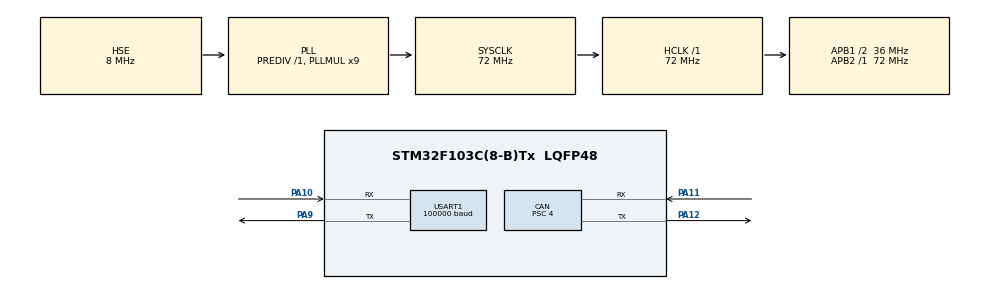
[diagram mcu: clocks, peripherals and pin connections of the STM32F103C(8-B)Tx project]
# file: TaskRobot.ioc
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CAN.BS1=CAN_BS1_6TQ
CAN.BS2=CAN_BS2_2TQ
CAN.CalculateBaudRate=1000000
CAN.CalculateTimeBit=1000
CAN.CalculateTimeQuantum=111.11111111111111
CAN.Prescaler=4
Dma.Request0=USART1_RX
Dma.USART1_RX.0.Direction=DMA_PERIPH_TO_MEMORY
Dma.USART1_RX.0.Instance=DMA1_Channel5
Dma.USART1_RX.0.MemDataAlignment=DMA_MDATAALIGN_BYTE
Dma.USART1_RX.0.MemInc=DMA_MINC_ENABLE
Dma.USART1_RX.0.Mode=DMA_NORMAL
Dma.USART1_RX.0.PeriphDataAlignment=DMA_PDATAALIGN_BYTE
Dma.USART1_RX.0.PeriphInc=DMA_PINC_DISABLE
Dma.USART1_RX.0.Priority=DMA_PRIORITY_LOW
Mcu.Family=STM32F1
Mcu.Name=STM32F103C(8-B)Tx
Mcu.Package=LQFP48
NVIC.DMA1_Channel5_IRQn=true\:0\:0\:false\:false\:true\:false\:true\:true
NVIC.PriorityGroup=NVIC_PRIORITYGROUP_4
NVIC.USART1_IRQn=true\:0\:0\:false\:false\:true\:true\:true\:true
NVIC.USB_LP_CAN1_RX0_IRQn=true\:0\:0\:false\:false\:true\:true\:true\:true
PA10.Mode=Asynchronous
PA10.Signal=USART1_RX
PA11.Mode=CAN_Activate
PA11.Signal=CAN_RX
PA12.Mode=CAN_Activate
PA12.Signal=CAN_TX
PA9.Mode=Asynchronous
PA9.Signal=USART1_TX
PD0-OSC_IN.Mode=HSE-External-Oscillator
PD0-OSC_IN.Signal=RCC_OSC_IN
PD1-OSC_OUT.Mode=HSE-External-Oscillator
PD1-OSC_OUT.Signal=RCC_OSC_OUT
ProjectManager.HeapSize=0x200
ProjectManager.StackSize=0x400
ProjectManager.TargetToolchain=Makefile
RCC.AHBFreq_Value=72000000
RCC.APB1CLKDivider=RCC_HCLK_DIV2
RCC.APB1Freq_Value=36000000
RCC.APB1TimFreq_Value=72000000
RCC.APB2Freq_Value=72000000
RCC.APB2TimFreq_Value=72000000
RCC.HCLKFreq_Value=72000000
RCC.PLLMUL=RCC_PLL_MUL9
RCC.PLLSourceVirtual=RCC_PLLSOURCE_HSE
RCC.SYSCLKFreq_VALUE=72000000
RCC.SYSCLKSource=RCC_SYSCLKSOURCE_PLLCLK
RCC.USBFreq_Value=72000000
USART1.BaudRate=100000
USART1.Parity=PARITY_EVEN
USART1.VirtualMode=VM_ASYNC
USART1.WordLength=WORDLENGTH_9B
VP_SYS_VS_ND.Mode=No_Debug
board=custom

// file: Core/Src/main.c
/* USER CODE BEGIN Header */
/**
  ******************************************************************************
  * @file           : main.c
  * @brief          : Main program body
  ******************************************************************************
  * @attention
  *
  * Copyright (c) 2023 STMicroelectronics.
  * All rights reserved.
  *
  * This software is licensed under terms that can be found in the LICENSE file
  * in the root directory of this software component.
  * If no LICENSE file comes with this software, it is provided AS-IS.
  *
  ******************************************************************************
  */
/* USER CODE END Header */
#include "main.h"
#include "can.h"
#include "dma.h"
#include "usart.h"
#include "gpio.h"

/* USER CODE BEGIN Includes */
// #include "cppMain.hpp"
/* USER CODE END Includes */

void SystemClock_Config(void);

int main(void)
{

  /* MCU Configuration--------------------------------------------------------*/

  /* Reset of all peripherals, Initializes the Flash interface and the Systick. */
  HAL_Init();

  /* Configure the system clock */
  SystemClock_Config();

  /* Initialize all configured peripherals */
  MX_GPIO_Init();
  MX_DMA_Init();
  MX_CAN_Init();
  MX_USART1_UART_Init();

  /* Infinite loop */
  /* USER CODE BEGIN WHILE */
  extern int cppMain();
  cppMain();

  while (1)
  {
    /* USER CODE END WHILE */

  }
}

void SystemClock_Config(void)
{
  RCC_OscInitTypeDef RCC_OscInitStruct = {0};
  RCC_ClkInitTypeDef RCC_ClkInitStruct = {0};

  /** Initializes the RCC Oscillators according to the specified parameters
  * in the RCC_OscInitTypeDef structure.
  */
  RCC_OscInitStruct.OscillatorType = RCC_OSCILLATORTYPE_HSE;
  RCC_OscInitStruct.HSEState = RCC_HSE_ON;
  RCC_OscInitStruct.HSEPredivValue = RCC_HSE_PREDIV_DIV1;
  RCC_OscInitStruct.HSIState = RCC_HSI_ON;
  RCC_OscInitStruct.PLL.PLLState = RCC_PLL_ON;
  RCC_OscInitStruct.PLL.PLLSource = RCC_PLLSOURCE_HSE;
  RCC_OscInitStruct.PLL.PLLMUL = RCC_PLL_MUL9;
  if (HAL_RCC_OscConfig(&RCC_OscInitStruct) != HAL_OK)
  {
    Error_Handler();
  }

  /** Initializes the CPU, AHB and APB buses clocks
  */
  RCC_ClkInitStruct.ClockType = RCC_CLOCKTYPE_HCLK|RCC_CLOCKTYPE_SYSCLK
                              |RCC_CLOCKTYPE_PCLK1|RCC_CLOCKTYPE_PCLK2;
  RCC_ClkInitStruct.SYSCLKSource = RCC_SYSCLKSOURCE_PLLCLK;
  RCC_ClkInitStruct.AHBCLKDivider = RCC_SYSCLK_DIV1;
  RCC_ClkInitStruct.APB1CLKDivider = RCC_HCLK_DIV2;
  RCC_ClkInitStruct.APB2CLKDivider = RCC_HCLK_DIV1;

  if (HAL_RCC_ClockConfig(&RCC_ClkInitStruct, FLASH_LATENCY_2) != HAL_OK)
  {
    Error_Handler();
  }
}

void Error_Handler(void)
{
  __disable_irq();
  while (1)
  {
  }
}
